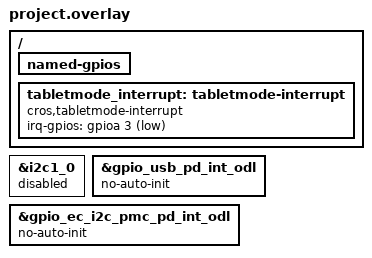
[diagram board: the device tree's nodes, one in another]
/* Copyright 2022 The ChromiumOS Authors
 * Use of this source code is governed by a BSD-style license that can be
 * found in the LICENSE file.
 */

#include "../cbi.dtsi"

#include "cbi.dtsi"
#include "generated.dtsi"
#include "keyboard.dtsi"
#include "overlay.dtsi"
#include "power_signals.dtsi"
#include "led_pins.dtsi"
#include "led_policy.dtsi"

/delete-node/ &gpio_acc_int_l;
/delete-node/ &gpio_imu_int_l;
/delete-node/ &gpio_tablet_mode_l;
/delete-node/ &i2c_ec_i2c_sensor;

/ {
	named-gpios {
		/delete-node/ sen_mode_ec_pch_int_odl;
	};

	tabletmode_interrupt: tabletmode-interrupt {
		compatible = "cros,tabletmode-interrupt";
		irq-gpios = <&gpioa 3 GPIO_ACTIVE_LOW>;
	};
};

&i2c1_0 {
	status = "disabled";
};

/* These GPIOS are initialized by the PDC driver */
&gpio_usb_pd_int_odl {
	no-auto-init;
};

&gpio_ec_i2c_pmc_pd_int_odl {
	no-auto-init;
};
